# AT32UC3A0256 device description
Architecture: AVR32_UC3; Family: AVR UC3
Registers are 32-bit, read-write, reset 0x0 unless marked. A register's access mark holds for its fields unless they carry their own. Offsets are from the block's base; [hi:lo] are bit positions; 'fields as' and 'values as' point back to an identical list.

## SSC — Synchronous Serial Controller
Instances: SSC 0xffff3400
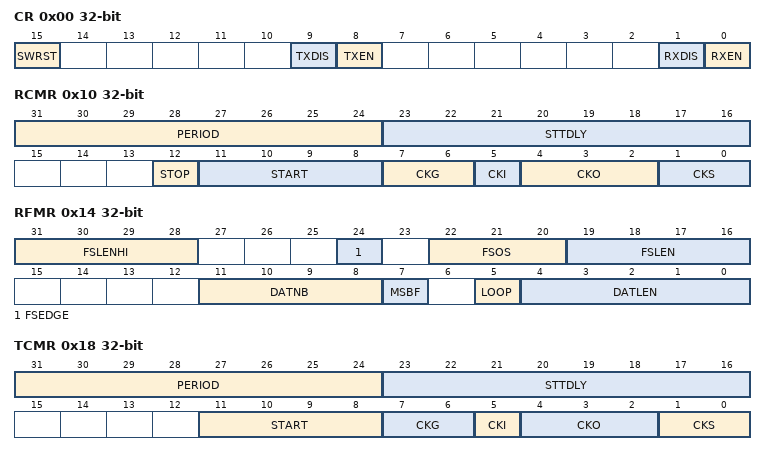
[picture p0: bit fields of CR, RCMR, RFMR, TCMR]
0x00 CR wo reset not defined — Control Register
  [15] SWRST — Software Reset
  [9] TXDIS — Transmit Disable
  [8] TXEN — Transmit Enable
  [1] RXDIS — Receive Disable
  [0] RXEN — Receive Enable
0x04 CMR — Clock Mode Register
  [11:0] DIV — Clock Divider
    0=NOT_ACTIVE
0x10 RCMR — Receive Clock Mode Register
  [31:24] PERIOD — Receive Period Divider Selection
  [23:16] STTDLY — Receive Start Delay
  [12] STOP — Receive Stop Selection
  [11:8] START — Receive Start Selection
    0=CONTINOUS; 1=RECEIVE_START; 2=DETECT_LOW_TF; 3=DETECT_HIGH_TF; 4=DETECT_FALLING_TF; 5=DETECT_RISING_TF; 6=DETECT_LEVEL_CHANGE_TF; 7=DETECT_ANY_EDGE_TF
  [7:6] CKG — Receive Clock Gating Selection
    0=NONE (None, continuous clock); 1=LOW (Receive Clock enabled only if RX_FRAME_SYNC is low); 2=HIGH (Receive Clock enabled only if RX_FRAME_SYNC is high)
  [5] CKI — Receive Clock Inversion
  [4:2] CKO — Clock Output Mode Selection
    0=INPUT_ONLY (No receive clock output mode, RX_CLOCK pin is input-only); 1=CONTINOUS_CLOCK_OUTPUT (Continuous receive clock, RX_CLOCK pin is output); 2=CLOCK_DURING_DATA (Receive clock only during data transfers, RX_CLOCK pin is output)
  [1:0] CKS — Receive Clock Selection
    0=DIV_CLOCK (Divided clock); 1=TK_CLOCK (TX_CLOCK clock signal); 2=RK_PIN (RX_CLOCK pin)
0x14 RFMR — Receive Frame Mode Register
  [31:28] FSLENHI — Receive Frame Sync Length High Part
  [24] FSEDGE — Frame Sync Edge Detection
  [22:20] FSOS — Receive Frame Sync Output Selection
    0=INPUT_ONLY; 1=NEG_PULSE; 2=POS_PULSE; 3=LOW_DURING_DATA; 4=HIGH_DURING_DATA; 5=TOGGLE_DATA_START
  [19:16] FSLEN — Receive Frame Sync Length
  [11:8] DATNB — Data Number per Frame
  [7] MSBF — Most Significant Bit First
  [5] LOOP — Loop Mode
  [4:0] DATLEN — Data Length
0x18 TCMR — Transmit Clock Mode Register
  [31:24] PERIOD — Transmit Period Divider Selection
  [23:16] STTDLY — Transmit Start Delay
  [11:8] START — Transmit Start Selection
    values as RCMR.START
  [7:6] CKG — Transmit Clock Gating Selection
    values as RCMR.CKG
  [5] CKI — Transmit Clock Inversion
  [4:2] CKO — Transmit Clock Output Mode Selection
    values as RCMR.CKO
  [1:0] CKS — Transmit Clock Selection
    values as RCMR.CKS
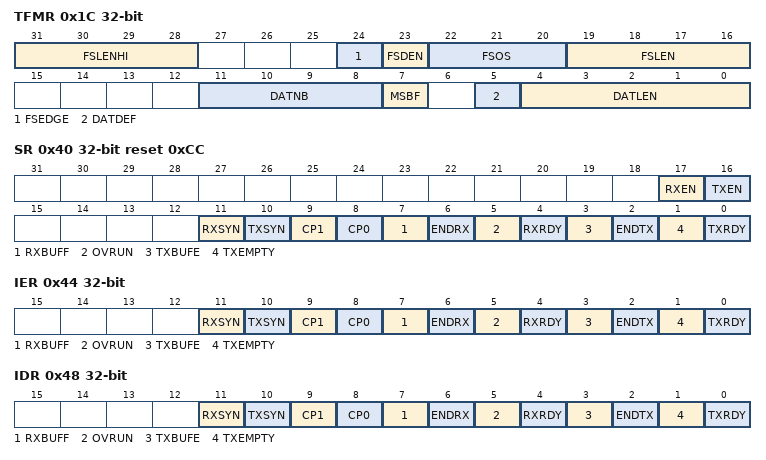
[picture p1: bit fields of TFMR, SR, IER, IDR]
0x1C TFMR — Transmit Frame Mode Register
  [31:28] FSLENHI — Receive Frame Sync Length High Part
  [24] FSEDGE — Frame Sync Edge Detection
  [23] FSDEN — Frame Sync Data Enable
  [22:20] FSOS — Transmit Frame Sync Output Selection
    values as RFMR.FSOS
  [19:16] FSLEN — Transmit Frame Sync Length
  [11:8] DATNB — Data Number per frame
  [7] MSBF — Most Significant Bit First
  [5] DATDEF — Data Default Value
  [4:0] DATLEN — Data Length
0x20 RHR ro — Receive Holding Register
  [31:0] RDAT — Receive Data
0x24 THR wo reset not defined — Transmit Holding Register
  [31:0] TDAT — Transmit Data
0x30 RSHR ro — Recieve Sync. Holding Register
  [15:0] RSDAT — Receive Synchronization Data
0x34 TSHR — Transmit Sync. Holding Register
  [15:0] TSDAT — Transmit Synchronization Data
0x38 RC0R access not given — SSC Receive Compare 0 Register
  [15:0] CP0 — Receive Compare Data 0
0x3C RC1R access not given — SSC Receive Compare 1 Register
  [15:0] CP1 — Receive Compare Data 1
0x40 SR ro reset 0xCC — Status Register
  [17] RXEN — Receive Enable
  [16] TXEN — Transmit Enable
  [11] RXSYN — Receive Sync
  [10] TXSYN — Transmit Sync
  [9] CP1 — Compare 1
  [8] CP0 — Compare 0
  [7] RXBUFF — Receive Buffer Full
  [6] ENDRX — End of Reception
  [5] OVRUN — Receive Overrun
  [4] RXRDY — Receive Ready
  [3] TXBUFE — Transmit Buffer Empty
  [2] ENDTX — End of Transmission
  [1] TXEMPTY — Transmit Empty
  [0] TXRDY — Transmit Ready
0x44 IER wo reset not defined — Interrupt Enable Register
  [11] RXSYN — Rx Sync Interrupt Enable
  [10] TXSYN — Tx Sync Interrupt Enable
  [9] CP1 — Compare 1 Interrupt Enable
  [8] CP0 — Compare 0 Interrupt Enable
  [7] RXBUFF — Receive Buffer Full Interrupt Enable
  [6] ENDRX — End of Reception Interrupt Enable
  [5] OVRUN — Receive Overrun Interrupt Enable
  [4] RXRDY — Receiver Ready Interrupt Enable
  [3] TXBUFE — Transmit Buffer Empty Interrupt Enable
  [2] ENDTX — End of Transmission Interrupt Enable
  [1] TXEMPTY — Transmit Empty Interrupt Enable
  [0] TXRDY — Transmit Ready Interrupt Enable
0x48 IDR wo reset not defined — Interrupt Disable Register
  [11] RXSYN — Rx Sync Interrupt Disable
  [10] TXSYN — Tx Sync Interrupt Disable
  [9] CP1 — Compare 1 Interrupt Disable
  [8] CP0 — Compare 0 Interrupt Disable
  [7] RXBUFF — Receive Buffer Full Interrupt Disable
  [6] ENDRX — End of Reception Interrupt Disable
  [5] OVRUN — Receive Overrun Interrupt Disable
  [4] RXRDY — Receive Ready Interrupt Disable
  [3] TXBUFE — Transmit Buffer Empty Interrupt Disable
  [2] ENDTX — End of Transmission Interrupt Disable
  [1] TXEMPTY — Transmit Empty Interrupt Disable
  [0] TXRDY — Transmit Ready Interrupt Disable
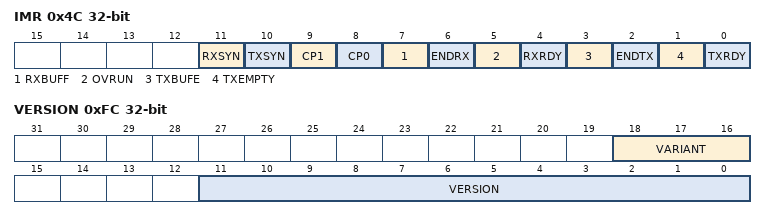
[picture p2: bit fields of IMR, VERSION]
0x4C IMR ro — Interrupt Mask Register
  [11] RXSYN — Rx Sync Interrupt Mask
  [10] TXSYN — Tx Sync Interrupt Mask
  [9] CP1 — Compare 1 Interrupt Mask
  [8] CP0 — Compare 0 Interrupt Mask
  [7] RXBUFF — Receive Buffer Full Interrupt Mask
  [6] ENDRX — End of Reception Interrupt Mask
  [5] OVRUN — Receive Overrun Interrupt Mask
  [4] RXRDY — Receive Ready Interrupt Mask
  [3] TXBUFE — Transmit Buffer Empty Interrupt Mask
  [2] ENDTX — End of Transmission Interrupt Mask
  [1] TXEMPTY — Transmit Empty Interrupt Mask
  [0] TXRDY — Transmit Ready Interrupt Mask
0xFC VERSION ro reset not defined
  [18:16] VARIANT, [11:0] VERSION
